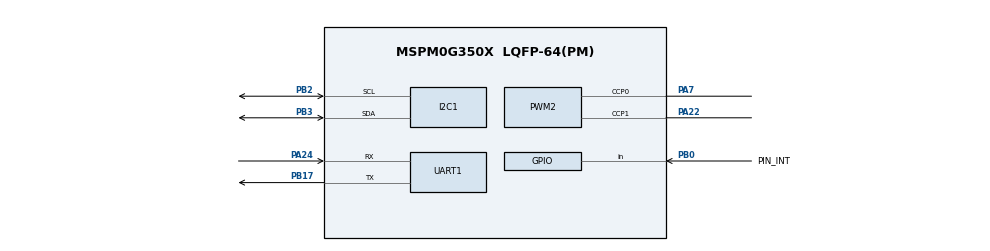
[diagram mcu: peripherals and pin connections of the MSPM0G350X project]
/**
 * @cliArgs --device "MSPM0G350X" --part "Default" --package "LQFP-64(PM)" --product "mspm0_sdk@2.04.00.06"
 * @versions {"tool":"1.24.0+4110"}
 */

/**
 * Import the modules used in this configuration.
 */
const GPIO   = scripting.addModule("/ti/driverlib/GPIO", {}, false);
const GPIO1  = GPIO.addInstance();
const GPIO2  = GPIO.addInstance();
const GPIO3  = GPIO.addInstance();
const GPIO4  = GPIO.addInstance();
const GPIO5  = GPIO.addInstance();
const GPIO6  = GPIO.addInstance();
const I2C    = scripting.addModule("/ti/driverlib/I2C", {}, false);
const I2C1   = I2C.addInstance();
const PWM    = scripting.addModule("/ti/driverlib/PWM", {}, false);
const PWM1   = PWM.addInstance();
const PWM2   = PWM.addInstance();
const SYSCTL = scripting.addModule("/ti/driverlib/SYSCTL");
const TIMER  = scripting.addModule("/ti/driverlib/TIMER", {}, false);
const TIMER1 = TIMER.addInstance();
const UART   = scripting.addModule("/ti/driverlib/UART", {}, false);
const UART1  = UART.addInstance();

/**
 * Write custom configuration values to the imported modules.
 */
const divider7       = system.clockTree["PLL_PDIV"];
divider7.divideValue = 2;

const divider9       = system.clockTree["UDIV"];
divider9.divideValue = 2;

const multiplier2         = system.clockTree["PLL_QDIV"];
multiplier2.multiplyValue = 5;

const mux8       = system.clockTree["HSCLKMUX"];
mux8.inputSelect = "HSCLKMUX_SYSPLL2X";

GPIO1.$name                               = "GPIO_MPU6050";
GPIO1.associatedPins[0].$name             = "PIN_INT";
GPIO1.associatedPins[0].direction         = "INPUT";
GPIO1.associatedPins[0].internalResistor  = "PULL_UP";
GPIO1.associatedPins[0].interruptEn       = true;
GPIO1.associatedPins[0].polarity          = "FALL";
GPIO1.associatedPins[0].assignedPin       = "0";
GPIO1.associatedPins[0].interruptPriority = "1";
GPIO1.associatedPins[0].pin.$assign       = "PB0";

const Board = scripting.addModule("/ti/driverlib/Board", {}, false);

GPIO2.$name                          = "GPIO_OLED";
GPIO2.associatedPins.create(2);
GPIO2.associatedPins[0].$name        = "PIN_SDA";
GPIO2.associatedPins[0].assignedPort = "PORTB";
GPIO2.associatedPins[0].assignedPin  = "15";
GPIO2.associatedPins[1].$name        = "PIN_SCL";
GPIO2.associatedPins[1].assignedPort = "PORTA";
GPIO2.associatedPins[1].assignedPin  = "17";

GPIO3.$name                              = "GPIO_Trail";
GPIO3.port                               = "PORTA";
GPIO3.associatedPins.create(2);
GPIO3.associatedPins[0].$name            = "PIN_Trail_DAT";
GPIO3.associatedPins[0].assignedPin      = "12";
GPIO3.associatedPins[0].direction        = "INPUT";
GPIO3.associatedPins[0].internalResistor = "PULL_UP";
GPIO3.associatedPins[1].assignedPin      = "13";
GPIO3.associatedPins[1].$name            = "PIN_Trail_CLK";

GPIO4.port                          = "PORTA";
GPIO4.$name                         = "GPIO_595";
GPIO4.associatedPins.create(3);
GPIO4.associatedPins[0].$name       = "PIN_595STCP";
GPIO4.associatedPins[0].assignedPin = "14";
GPIO4.associatedPins[1].$name       = "PIN_595SHCP";
GPIO4.associatedPins[1].assignedPin = "15";
GPIO4.associatedPins[2].assignedPin = "25";
GPIO4.associatedPins[2].$name       = "PIN_595DS";

GPIO5.$name                              = "GPIO_Key";
GPIO5.port                               = "PORTB";
GPIO5.associatedPins.create(4);
GPIO5.associatedPins[0].$name            = "PIN_Key1";
GPIO5.associatedPins[0].direction        = "INPUT";
GPIO5.associatedPins[0].internalResistor = "PULL_UP";
GPIO5.associatedPins[0].assignedPin      = "12";
GPIO5.associatedPins[1].assignedPin      = "8";
GPIO5.associatedPins[1].direction        = "INPUT";
GPIO5.associatedPins[1].$name            = "PIN_Key2";
GPIO5.associatedPins[1].internalResistor = "PULL_UP";
GPIO5.associatedPins[2].assignedPin      = "9";
GPIO5.associatedPins[2].direction        = "INPUT";
GPIO5.associatedPins[2].$name            = "PIN_Key3";
GPIO5.associatedPins[2].internalResistor = "PULL_UP";
GPIO5.associatedPins[3].assignedPin      = "10";
GPIO5.associatedPins[3].direction        = "INPUT";
GPIO5.associatedPins[3].$name            = "PIN_Key4";
GPIO5.associatedPins[3].internalResistor = "PULL_UP";

GPIO6.$name                               = "GPIO_Encoder";
GPIO6.port                                = "PORTB";
GPIO6.associatedPins.create(8);
GPIO6.associatedPins[0].assignedPin       = "4";
GPIO6.associatedPins[0].$name             = "L1_E1";
GPIO6.associatedPins[0].direction         = "INPUT";
GPIO6.associatedPins[0].interruptEn       = true;
GPIO6.associatedPins[0].polarity          = "RISE";
GPIO6.associatedPins[0].interruptPriority = "1";
GPIO6.associatedPins[1].$name             = "L1_E2";
GPIO6.associatedPins[1].direction         = "INPUT";
GPIO6.associatedPins[1].assignedPin       = "5";
GPIO6.associatedPins[1].interruptEn       = true;
GPIO6.associatedPins[1].polarity          = "RISE";
GPIO6.associatedPins[1].interruptPriority = "1";
GPIO6.associatedPins[2].$name             = "L2_E1";
GPIO6.associatedPins[2].direction         = "INPUT";
GPIO6.associatedPins[2].assignedPin       = "6";
GPIO6.associatedPins[2].interruptEn       = true;
GPIO6.associatedPins[2].polarity          = "RISE";
GPIO6.associatedPins[2].interruptPriority = "1";
GPIO6.associatedPins[3].$name             = "L2_E2";
GPIO6.associatedPins[3].direction         = "INPUT";
GPIO6.associatedPins[3].assignedPin       = "7";
GPIO6.associatedPins[3].interruptEn       = true;
GPIO6.associatedPins[3].polarity          = "RISE";
GPIO6.associatedPins[3].interruptPriority = "1";
GPIO6.associatedPins[4].$name             = "R1_E1";
GPIO6.associatedPins[4].direction         = "INPUT";
GPIO6.associatedPins[4].interruptEn       = true;
GPIO6.associatedPins[4].polarity          = "RISE";
GPIO6.associatedPins[4].assignedPin       = "23";
GPIO6.associatedPins[4].interruptPriority = "1";
GPIO6.associatedPins[5].$name             = "R1_E2";
GPIO6.associatedPins[5].direction         = "INPUT";
GPIO6.associatedPins[5].interruptEn       = true;
GPIO6.associatedPins[5].polarity          = "RISE";
GPIO6.associatedPins[5].assignedPin       = "13";
GPIO6.associatedPins[5].interruptPriority = "1";
GPIO6.associatedPins[6].$name             = "R2_E1";
GPIO6.associatedPins[6].direction         = "INPUT";
GPIO6.associatedPins[6].interruptEn       = true;
GPIO6.associatedPins[6].polarity          = "RISE";
GPIO6.associatedPins[6].assignedPin       = "19";
GPIO6.associatedPins[6].interruptPriority = "1";
GPIO6.associatedPins[7].$name             = "R2_E2";
GPIO6.associatedPins[7].direction         = "INPUT";
GPIO6.associatedPins[7].interruptEn       = true;
GPIO6.associatedPins[7].polarity          = "RISE";
GPIO6.associatedPins[7].assignedPin       = "18";
GPIO6.associatedPins[7].interruptPriority = "1";

I2C1.$name                             = "I2C_MPU6050";
I2C1.basicEnableController             = true;
I2C1.basicControllerStandardBusSpeed   = "Fast";
I2C1.peripheral.$assign                = "I2C1";
I2C1.peripheral.sdaPin.$assign         = "PB3";
I2C1.peripheral.sclPin.$assign         = "PB2";
I2C1.sdaPinConfig.$name                = "ti_driverlib_gpio_GPIOPinGeneric0";
I2C1.sdaPinConfig.hideOutputInversion  = scripting.forceWrite(false);
I2C1.sdaPinConfig.onlyInternalResistor = scripting.forceWrite(false);
I2C1.sdaPinConfig.passedPeripheralType = scripting.forceWrite("Digital");
I2C1.sclPinConfig.$name                = "ti_driverlib_gpio_GPIOPinGeneric1";
I2C1.sclPinConfig.hideOutputInversion  = scripting.forceWrite(false);
I2C1.sclPinConfig.onlyInternalResistor = scripting.forceWrite(false);
I2C1.sclPinConfig.passedPeripheralType = scripting.forceWrite("Digital");

PWM1.$name                              = "PWM_L";
PWM1.clockDivider                       = 8;
PWM1.timerCount                         = 10000;
PWM1.timerStartTimer                    = true;
PWM1.peripheral.$assign                 = "TIMA0";
PWM1.PWM_CHANNEL_0.$name                = "ti_driverlib_pwm_PWMTimerCC0";
PWM1.PWM_CHANNEL_0.ccValue              = 3999;
PWM1.PWM_CHANNEL_1.$name                = "ti_driverlib_pwm_PWMTimerCC1";
PWM1.PWM_CHANNEL_1.ccValue              = 3999;
PWM1.ccp0PinConfig.direction            = scripting.forceWrite("OUTPUT");
PWM1.ccp0PinConfig.hideOutputInversion  = scripting.forceWrite(false);
PWM1.ccp0PinConfig.onlyInternalResistor = scripting.forceWrite(false);
PWM1.ccp0PinConfig.passedPeripheralType = scripting.forceWrite("Digital");
PWM1.ccp0PinConfig.$name                = "ti_driverlib_gpio_GPIOPinGeneric4";
PWM1.ccp1PinConfig.direction            = scripting.forceWrite("OUTPUT");
PWM1.ccp1PinConfig.hideOutputInversion  = scripting.forceWrite(false);
PWM1.ccp1PinConfig.onlyInternalResistor = scripting.forceWrite(false);
PWM1.ccp1PinConfig.passedPeripheralType = scripting.forceWrite("Digital");
PWM1.ccp1PinConfig.$name                = "ti_driverlib_gpio_GPIOPinGeneric5";

PWM2.$name                              = "PWM_R";
PWM2.timerCount                         = 10000;
PWM2.timerStartTimer                    = true;
PWM2.clockDivider                       = 4;
PWM2.peripheral.$assign                 = "TIMG8";
PWM2.peripheral.ccp0Pin.$assign         = "PA7";
PWM2.peripheral.ccp1Pin.$assign         = "PA22";
PWM2.PWM_CHANNEL_0.$name                = "ti_driverlib_pwm_PWMTimerCC2";
PWM2.PWM_CHANNEL_0.ccValue              = 3999;
PWM2.PWM_CHANNEL_1.$name                = "ti_driverlib_pwm_PWMTimerCC3";
PWM2.PWM_CHANNEL_1.ccValue              = 3999;
PWM2.ccp0PinConfig.direction            = scripting.forceWrite("OUTPUT");
PWM2.ccp0PinConfig.hideOutputInversion  = scripting.forceWrite(false);
PWM2.ccp0PinConfig.onlyInternalResistor = scripting.forceWrite(false);
PWM2.ccp0PinConfig.passedPeripheralType = scripting.forceWrite("Digital");
PWM2.ccp0PinConfig.$name                = "ti_driverlib_gpio_GPIOPinGeneric6";
PWM2.ccp1PinConfig.direction            = scripting.forceWrite("OUTPUT");
PWM2.ccp1PinConfig.hideOutputInversion  = scripting.forceWrite(false);
PWM2.ccp1PinConfig.onlyInternalResistor = scripting.forceWrite(false);
PWM2.ccp1PinConfig.passedPeripheralType = scripting.forceWrite("Digital");
PWM2.ccp1PinConfig.$name                = "ti_driverlib_gpio_GPIOPinGeneric7";

SYSCTL.forceDefaultClkConfig = true;
SYSCTL.clockTreeEn           = true;
scripting.suppress("For best practices when the CPUCLK is running at 32MHz and above, clear the flash status bit using DL_FlashCTL_executeClearStatus\\(\\) before executing any flash operation\\. Otherwise there may be false positives\\.", SYSCTL);

TIMER1.$name              = "TIMER_0";
TIMER1.timerPeriod        = "10 ms";
TIMER1.timerMode          = "PERIODIC";
TIMER1.interrupts         = ["ZERO"];
TIMER1.peripheral.$assign = "TIMG12";

UART1.$name                    = "UART_0";
UART1.targetBaudRate           = 115200;
UART1.peripheral.$assign       = "UART2";
UART1.peripheral.rxPin.$assign = "PA24";
UART1.peripheral.txPin.$assign = "PB17";
UART1.txPinConfig.$name        = "ti_driverlib_gpio_GPIOPinGeneric2";
UART1.rxPinConfig.$name        = "ti_driverlib_gpio_GPIOPinGeneric3";

/**
 * Pinmux solution for unlocked pins/peripherals. This ensures that minor changes to the automatic solver in a future
 * version of the tool will not impact the pinmux you originally saw.  These lines can be completely deleted in order to
 * re-solve from scratch.
 */
Board.peripheral.$suggestSolution            = "DEBUGSS";
Board.peripheral.swclkPin.$suggestSolution   = "PA20";
Board.peripheral.swdioPin.$suggestSolution   = "PA19";
GPIO2.associatedPins[0].pin.$suggestSolution = "PB15";
GPIO2.associatedPins[1].pin.$suggestSolution = "PA17";
GPIO3.associatedPins[0].pin.$suggestSolution = "PA12";
GPIO3.associatedPins[1].pin.$suggestSolution = "PA13";
GPIO4.associatedPins[0].pin.$suggestSolution = "PA14";
GPIO4.associatedPins[1].pin.$suggestSolution = "PA15";
GPIO4.associatedPins[2].pin.$suggestSolution = "PA25";
GPIO5.associatedPins[0].pin.$suggestSolution = "PB12";
GPIO5.associatedPins[1].pin.$suggestSolution = "PB8";
GPIO5.associatedPins[2].pin.$suggestSolution = "PB9";
GPIO5.associatedPins[3].pin.$suggestSolution = "PB10";
GPIO6.associatedPins[0].pin.$suggestSolution = "PB4";
GPIO6.associatedPins[1].pin.$suggestSolution = "PB5";
GPIO6.associatedPins[2].pin.$suggestSolution = "PB6";
GPIO6.associatedPins[3].pin.$suggestSolution = "PB7";
GPIO6.associatedPins[4].pin.$suggestSolution = "PB23";
GPIO6.associatedPins[5].pin.$suggestSolution = "PB13";
GPIO6.associatedPins[6].pin.$suggestSolution = "PB19";
GPIO6.associatedPins[7].pin.$suggestSolution = "PB18";
PWM1.peripheral.ccp0Pin.$suggestSolution     = "PA0";
PWM1.peripheral.ccp1Pin.$suggestSolution     = "PA1";
